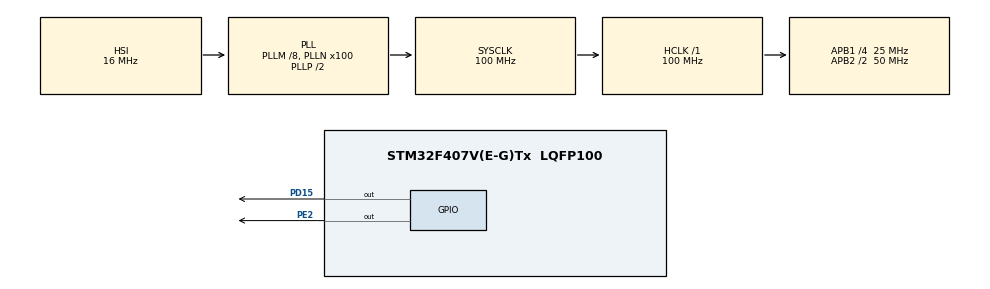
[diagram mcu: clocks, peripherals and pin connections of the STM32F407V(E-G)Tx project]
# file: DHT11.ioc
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Mcu.Family=STM32F4
Mcu.Name=STM32F407V(E-G)Tx
Mcu.Package=LQFP100
NVIC.PriorityGroup=NVIC_PRIORITYGROUP_4
PD15.GPIO_Speed=GPIO_SPEED_FREQ_VERY_HIGH
PD15.Signal=GPIO_Output
PE2.GPIO_Speed=GPIO_SPEED_FREQ_VERY_HIGH
PE2.PinState=GPIO_PIN_RESET
PE2.Signal=GPIO_Output
ProjectManager.HeapSize=0x200
ProjectManager.StackSize=0x400
ProjectManager.TargetToolchain=STM32CubeIDE
RCC.48MHZClocksFreq_Value=50000000
RCC.AHBFreq_Value=100000000
RCC.APB1CLKDivider=RCC_HCLK_DIV4
RCC.APB1Freq_Value=25000000
RCC.APB1TimFreq_Value=50000000
RCC.APB2CLKDivider=RCC_HCLK_DIV2
RCC.APB2Freq_Value=50000000
RCC.APB2TimFreq_Value=100000000
RCC.CortexFreq_Value=100000000
RCC.HCLKFreq_Value=100000000
RCC.HSE_VALUE=25000000
RCC.HSI_VALUE=16000000
RCC.LSE_VALUE=32768
RCC.PLLM=8
RCC.PLLN=100
RCC.SYSCLKFreq_VALUE=100000000
RCC.SYSCLKSource=RCC_SYSCLKSOURCE_PLLCLK
RCC.VCOOutputFreq_Value=200000000
TIM6.AutoReloadPreload=TIM_AUTORELOAD_PRELOAD_ENABLE
TIM6.Prescaler=49
VP_TIM6_VS_ClockSourceINT.Mode=Enable_Timer
board=custom

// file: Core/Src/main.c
/* USER CODE BEGIN Header */
/**
  ******************************************************************************
  * @file           : main.c
  * @brief          : Main program body
  ******************************************************************************
  * @attention
  *
  * <h2><center>&copy; Copyright (c) 2022 STMicroelectronics.
  * All rights reserved.</center></h2>
  *
  * This software component is licensed by ST under BSD 3-Clause license,
  * the "License"; You may not use this file except in compliance with the
  * License. You may obtain a copy of the License at:
  *                        opensource.org/licenses/BSD-3-Clause
  *
  ******************************************************************************
  */
/* USER CODE END Header */
#include "main.h"

/* USER CODE BEGIN Includes */
#include "DHT11.h"
/* USER CODE END Includes */

TIM_HandleTypeDef htim6;

/* USER CODE BEGIN PV */

__IO uint8_t temperature;
__IO uint8_t humidity;

/* USER CODE END PV */

void SystemClock_Config(void);
static void MX_GPIO_Init(void);
static void MX_TIM6_Init(void);

int main(void)
{

  /* MCU Configuration--------------------------------------------------------*/

  /* Reset of all peripherals, Initializes the Flash interface and the Systick. */
  HAL_Init();

  /* Configure the system clock */
  SystemClock_Config();

  /* Initialize all configured peripherals */
  MX_GPIO_Init();
  MX_TIM6_Init();
  /* USER CODE BEGIN 2 */

  if(HAL_TIM_Base_Start(&htim6) != HAL_OK)
	  Error_Handler();

  /* USER CODE END 2 */

  /* Infinite loop */
  while (1)
  {

    /* USER CODE BEGIN 3 */
	  StartSignal(GPIOE, GPIO_PIN_2);
	  if(GetResponse(GPIOE,GPIO_PIN_2)==TimeOutt)
		  Error_Handler();
	  GetResults(GPIOE, (uint8_t*)&temperature,(uint8_t*)&humidity, GPIO_PIN_2);
	  HAL_Delay(3000);
  }
  /* USER CODE END 3 */
}

void SystemClock_Config(void)
{
  RCC_OscInitTypeDef RCC_OscInitStruct = {0};
  RCC_ClkInitTypeDef RCC_ClkInitStruct = {0};

  /** Configure the main internal regulator output voltage
  */
  __HAL_RCC_PWR_CLK_ENABLE();
  __HAL_PWR_VOLTAGESCALING_CONFIG(PWR_REGULATOR_VOLTAGE_SCALE1);
  /** Initializes the RCC Oscillators according to the specified parameters
  * in the RCC_OscInitTypeDef structure.
  */
  RCC_OscInitStruct.OscillatorType = RCC_OSCILLATORTYPE_HSI;
  RCC_OscInitStruct.HSIState = RCC_HSI_ON;
  RCC_OscInitStruct.HSICalibrationValue = RCC_HSICALIBRATION_DEFAULT;
  RCC_OscInitStruct.PLL.PLLState = RCC_PLL_ON;
  RCC_OscInitStruct.PLL.PLLSource = RCC_PLLSOURCE_HSI;
  RCC_OscInitStruct.PLL.PLLM = 8;
  RCC_OscInitStruct.PLL.PLLN = 100;
  RCC_OscInitStruct.PLL.PLLP = RCC_PLLP_DIV2;
  RCC_OscInitStruct.PLL.PLLQ = 4;
  if (HAL_RCC_OscConfig(&RCC_OscInitStruct) != HAL_OK)
  {
    Error_Handler();
  }
  /** Initializes the CPU, AHB and APB buses clocks
  */
  RCC_ClkInitStruct.ClockType = RCC_CLOCKTYPE_HCLK|RCC_CLOCKTYPE_SYSCLK
                              |RCC_CLOCKTYPE_PCLK1|RCC_CLOCKTYPE_PCLK2;
  RCC_ClkInitStruct.SYSCLKSource = RCC_SYSCLKSOURCE_PLLCLK;
  RCC_ClkInitStruct.AHBCLKDivider = RCC_SYSCLK_DIV1;
  RCC_ClkInitStruct.APB1CLKDivider = RCC_HCLK_DIV4;
  RCC_ClkInitStruct.APB2CLKDivider = RCC_HCLK_DIV2;

  if (HAL_RCC_ClockConfig(&RCC_ClkInitStruct, FLASH_LATENCY_3) != HAL_OK)
  {
    Error_Handler();
  }
}

static void MX_TIM6_Init(void)
{

  TIM_MasterConfigTypeDef sMasterConfig = {0};

  htim6.Instance = TIM6;
  htim6.Init.Prescaler = 49;
  htim6.Init.CounterMode = TIM_COUNTERMODE_UP;
  htim6.Init.Period = 65535;
  htim6.Init.AutoReloadPreload = TIM_AUTORELOAD_PRELOAD_ENABLE;
  if (HAL_TIM_Base_Init(&htim6) != HAL_OK)
  {
    Error_Handler();
  }
  sMasterConfig.MasterOutputTrigger = TIM_TRGO_RESET;
  sMasterConfig.MasterSlaveMode = TIM_MASTERSLAVEMODE_DISABLE;
  if (HAL_TIMEx_MasterConfigSynchronization(&htim6, &sMasterConfig) != HAL_OK)
  {
    Error_Handler();
  }

}

static void MX_GPIO_Init(void)
{
  GPIO_InitTypeDef GPIO_InitStruct = {0};

  /* GPIO Ports Clock Enable */
  __HAL_RCC_GPIOE_CLK_ENABLE();
  __HAL_RCC_GPIOD_CLK_ENABLE();

  /*Configure GPIO pin Output Level */
  HAL_GPIO_WritePin(GPIOE, GPIO_PIN_2, GPIO_PIN_RESET);

  /*Configure GPIO pin Output Level */
  HAL_GPIO_WritePin(GPIOD, GPIO_PIN_15, GPIO_PIN_RESET);

  /*Configure GPIO pin : PE2 */
  GPIO_InitStruct.Pin = GPIO_PIN_2;
  GPIO_InitStruct.Mode = GPIO_MODE_OUTPUT_PP;
  GPIO_InitStruct.Pull = GPIO_NOPULL;
  GPIO_InitStruct.Speed = GPIO_SPEED_FREQ_VERY_HIGH;
  HAL_GPIO_Init(GPIOE, &GPIO_InitStruct);

  /*Configure GPIO pin : PD15 */
  GPIO_InitStruct.Pin = GPIO_PIN_15;
  GPIO_InitStruct.Mode = GPIO_MODE_OUTPUT_PP;
  GPIO_InitStruct.Pull = GPIO_NOPULL;
  GPIO_InitStruct.Speed = GPIO_SPEED_FREQ_VERY_HIGH;
  HAL_GPIO_Init(GPIOD, &GPIO_InitStruct);

}

void Error_Handler(void)
{
  __disable_irq();
  while (1)
  {
  }
}

/************************ (C) COPYRIGHT STMicroelectronics *****END OF FILE****/
